AUTOSAR XML (schema 4-3-0)
package /ComponentTypes
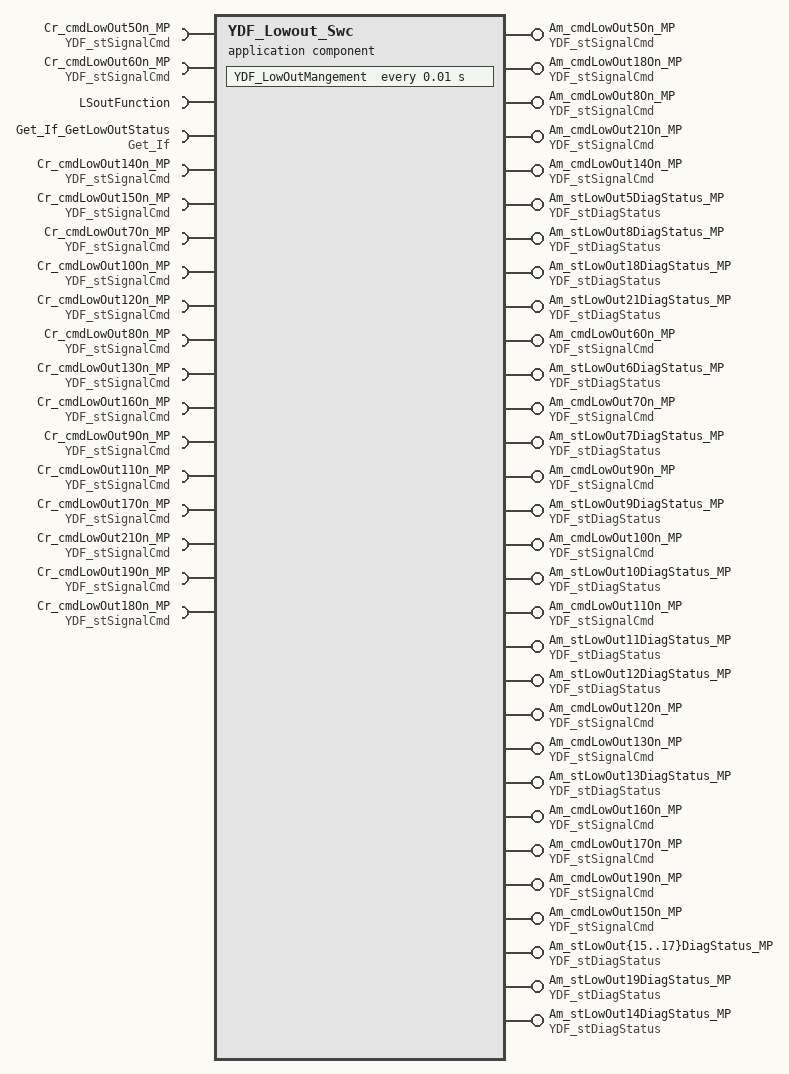
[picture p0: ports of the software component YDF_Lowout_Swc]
  application sw component type YDF_Lowout_Swc
    require port Cr_cmdLowOut5On_MP: nonqueued-receiver-com-spec{data-element=SignalCmd, init-value=0}, required-interface=YDF_stSignalCmd
    require port Cr_cmdLowOut6On_MP: nonqueued-receiver-com-spec{data-element=SignalCmd, init-value=0}, required-interface=YDF_stSignalCmd
    9 x provide port:
      Am_cmdLowOut5On_MP: nonqueued-sender-com-spec{data-element=SignalCmd, init-value=0}, provided-interface=YDF_stSignalCmd
      Am_cmdLowOut18On_MP: nonqueued-sender-com-spec{data-element=SignalCmd, init-value=0}, provided-interface=YDF_stSignalCmd
      Am_cmdLowOut8On_MP: nonqueued-sender-com-spec{data-element=SignalCmd, init-value=0}, provided-interface=YDF_stSignalCmd
      Am_cmdLowOut21On_MP: nonqueued-sender-com-spec{data-element=SignalCmd, init-value=0}, provided-interface=YDF_stSignalCmd
      Am_cmdLowOut14On_MP: nonqueued-sender-com-spec{data-element=SignalCmd, init-value=0}, provided-interface=YDF_stSignalCmd
      Am_stLowOut5DiagStatus_MP: nonqueued-sender-com-spec{data-element=DiagStatus, init-value=0}, provided-interface=YDF_stDiagStatus
      Am_stLowOut8DiagStatus_MP: nonqueued-sender-com-spec{data-element=DiagStatus, init-value=0}, provided-interface=YDF_stDiagStatus
      Am_stLowOut18DiagStatus_MP: nonqueued-sender-com-spec{data-element=DiagStatus, init-value=0}, provided-interface=YDF_stDiagStatus
      Am_stLowOut21DiagStatus_MP: nonqueued-sender-com-spec{data-element=DiagStatus, init-value=0}, provided-interface=YDF_stDiagStatus
    16 x require port:
      LSoutFunction: required-interface=LSoutFunction
        required-com-specs:
          Lowout{1..4}_Function
          Lowout20_Function
          Lowout{22..24}_Function
          Lowout_Lamp1_Function
          Lowout_Lamp2_Function
          Lowout_PWMOUT1_Function
          Lowout_PWMOUT2_Function
          Lowout{5..19}_Function
          Lowout21_Function
      Get_If_GetLowOutStatus: required-interface=Get_If
        required-com-specs:
          Get_Ad_Result
          Get_io_inResult
          Get_BTS_OutResult
          Get_CAN_ActiveInf
          Icu_17_GtmCcu6_PWMIN_CH{1..4}
          Icu_17_GtmCcu6_PWMIN_PWMSCB1
          Icu_17_GtmCcu6_PWMIN_PWMSCB2
          Icu_17_GtmCcu6_PWMIN_LAMPSCB1
          Icu_17_GtmCcu6_PWMIN_LAMPSCB2
          Get_Bottom_Ver
          Get_SentData
          Get_Level_OutResult
          Get_PwmOrLevel_OutResult
          Get_Motor_OutResult
      Cr_cmdLowOut14On_MP: nonqueued-receiver-com-spec{data-element=SignalCmd, init-value=0}, required-interface=YDF_stSignalCmd
      Cr_cmdLowOut15On_MP: nonqueued-receiver-com-spec{data-element=SignalCmd, init-value=0}, required-interface=YDF_stSignalCmd
      Cr_cmdLowOut7On_MP: nonqueued-receiver-com-spec{data-element=SignalCmd, init-value=0}, required-interface=YDF_stSignalCmd
      Cr_cmdLowOut10On_MP: nonqueued-receiver-com-spec{data-element=SignalCmd, init-value=0}, required-interface=YDF_stSignalCmd
      Cr_cmdLowOut12On_MP: nonqueued-receiver-com-spec{data-element=SignalCmd, init-value=0}, required-interface=YDF_stSignalCmd
      Cr_cmdLowOut8On_MP: nonqueued-receiver-com-spec{data-element=SignalCmd, init-value=0}, required-interface=YDF_stSignalCmd
      Cr_cmdLowOut13On_MP: nonqueued-receiver-com-spec{data-element=SignalCmd, init-value=0}, required-interface=YDF_stSignalCmd
      Cr_cmdLowOut16On_MP: nonqueued-receiver-com-spec{data-element=SignalCmd, init-value=0}, required-interface=YDF_stSignalCmd
      Cr_cmdLowOut9On_MP: nonqueued-receiver-com-spec{data-element=SignalCmd, init-value=0}, required-interface=YDF_stSignalCmd
      Cr_cmdLowOut11On_MP: nonqueued-receiver-com-spec{data-element=SignalCmd, init-value=0}, required-interface=YDF_stSignalCmd
      Cr_cmdLowOut17On_MP: nonqueued-receiver-com-spec{data-element=SignalCmd, init-value=0}, required-interface=YDF_stSignalCmd
      Cr_cmdLowOut21On_MP: nonqueued-receiver-com-spec{data-element=SignalCmd, init-value=0}, required-interface=YDF_stSignalCmd
      Cr_cmdLowOut19On_MP: nonqueued-receiver-com-spec{data-element=SignalCmd, init-value=0}, required-interface=YDF_stSignalCmd
      Cr_cmdLowOut18On_MP: nonqueued-receiver-com-spec{data-element=SignalCmd, init-value=0}, required-interface=YDF_stSignalCmd
    23 x provide port:
      Am_cmdLowOut6On_MP: nonqueued-sender-com-spec{data-element=SignalCmd, init-value=0}, provided-interface=YDF_stSignalCmd
      Am_stLowOut6DiagStatus_MP: nonqueued-sender-com-spec{data-element=DiagStatus, init-value=0}, provided-interface=YDF_stDiagStatus
      Am_cmdLowOut7On_MP: nonqueued-sender-com-spec{data-element=SignalCmd, init-value=0}, provided-interface=YDF_stSignalCmd
      Am_stLowOut7DiagStatus_MP: nonqueued-sender-com-spec{data-element=DiagStatus, init-value=0}, provided-interface=YDF_stDiagStatus
      Am_cmdLowOut9On_MP: nonqueued-sender-com-spec{data-element=SignalCmd, init-value=0}, provided-interface=YDF_stSignalCmd
      Am_stLowOut9DiagStatus_MP: nonqueued-sender-com-spec{data-element=DiagStatus, init-value=0}, provided-interface=YDF_stDiagStatus
      Am_cmdLowOut10On_MP: nonqueued-sender-com-spec{data-element=SignalCmd, init-value=0}, provided-interface=YDF_stSignalCmd
      Am_stLowOut10DiagStatus_MP: nonqueued-sender-com-spec{data-element=DiagStatus, init-value=0}, provided-interface=YDF_stDiagStatus
      Am_cmdLowOut11On_MP: nonqueued-sender-com-spec{data-element=SignalCmd, init-value=0}, provided-interface=YDF_stSignalCmd
      Am_stLowOut11DiagStatus_MP: nonqueued-sender-com-spec{data-element=DiagStatus, init-value=0}, provided-interface=YDF_stDiagStatus
      Am_stLowOut12DiagStatus_MP: nonqueued-sender-com-spec{data-element=DiagStatus, init-value=0}, provided-interface=YDF_stDiagStatus
      Am_cmdLowOut12On_MP: nonqueued-sender-com-spec{data-element=SignalCmd, init-value=0}, provided-interface=YDF_stSignalCmd
      Am_cmdLowOut13On_MP: nonqueued-sender-com-spec{data-element=SignalCmd, init-value=0}, provided-interface=YDF_stSignalCmd
      Am_stLowOut13DiagStatus_MP: nonqueued-sender-com-spec{data-element=DiagStatus, init-value=0}, provided-interface=YDF_stDiagStatus
      Am_cmdLowOut16On_MP: nonqueued-sender-com-spec{data-element=SignalCmd, init-value=0}, provided-interface=YDF_stSignalCmd
      Am_cmdLowOut17On_MP: nonqueued-sender-com-spec{data-element=SignalCmd, init-value=0}, provided-interface=YDF_stSignalCmd
      Am_cmdLowOut19On_MP: nonqueued-sender-com-spec{data-element=SignalCmd, init-value=0}, provided-interface=YDF_stSignalCmd
      Am_cmdLowOut15On_MP: nonqueued-sender-com-spec{data-element=SignalCmd, init-value=0}, provided-interface=YDF_stSignalCmd
      Am_stLowOut{15..17}DiagStatus_MP: nonqueued-sender-com-spec{data-element=DiagStatus, init-value=0}, provided-interface=YDF_stDiagStatus
      Am_stLowOut19DiagStatus_MP: nonqueued-sender-com-spec{data-element=DiagStatus, init-value=0}, provided-interface=YDF_stDiagStatus
      Am_stLowOut14DiagStatus_MP: nonqueued-sender-com-spec{data-element=DiagStatus, init-value=0}, provided-interface=YDF_stDiagStatus
    behavior YDF_Lowout_Swc_InternalBehavior
      timing event TMT_YDF_LowOutMangement: start-on-event=YDF_LowOutMangement, period=0.01
      runnable YDF_LowOutMangement
        data-receive-point-by-arguments:
          16 x access:
            REC_Cr_cmdLowOut{10..19}On_MP_SignalCmd: accessed-variable=Cr_cmdLowOut{10..19}On_MP.SignalCmd
            REC_Cr_cmdLowOut21On_MP_SignalCmd: accessed-variable=Cr_cmdLowOut21On_MP.SignalCmd
            REC_Cr_cmdLowOut{5..9}On_MP_SignalCmd: accessed-variable=Cr_cmdLowOut{5..9}On_MP.SignalCmd
        data-send-points:
          32 x access:
            SEND_Am_cmdLowOut{10..19}On_MP_SignalCmd: accessed-variable=Am_cmdLowOut{10..19}On_MP.SignalCmd
            SEND_Am_cmdLowOut21On_MP_SignalCmd: accessed-variable=Am_cmdLowOut21On_MP.SignalCmd
            SEND_Am_cmdLowOut{5..9}On_MP_SignalCmd: accessed-variable=Am_cmdLowOut{5..9}On_MP.SignalCmd
            SEND_Am_stLowOut{10..19}DiagStatus_MP_DiagStatus: accessed-variable=Am_stLowOut{10..19}DiagStatus_MP.DiagStatus
            SEND_Am_stLowOut21DiagStatus_MP_DiagStatus: accessed-variable=Am_stLowOut21DiagStatus_MP.DiagStatus
            SEND_Am_stLowOut{5..9}DiagStatus_MP_DiagStatus: accessed-variable=Am_stLowOut{5..9}DiagStatus_MP.DiagStatus
        17 x sync call:
          SC_Get_If_GetLowOutStatus_Get_Level_OutResult: operation=Get_If_GetLowOutStatus.Get_Level_OutResult
          SC_LSoutFunction_Lowout{10..19}_Function: operation=LSoutFunction.Lowout{10..19}_Function
          SC_LSoutFunction_Lowout21_Function: operation=LSoutFunction.Lowout21_Function
          SC_LSoutFunction_Lowout{5..9}_Function: operation=LSoutFunction.Lowout{5..9}_Function
  swc implementation YDF_Lowout_Swc_Implementation: behavior=YDF_Lowout_Swc_InternalBehavior
